VERSION ""

NS_ :

BS_:
BU_: Xsens_Sensor
BO_ 2147483648 VECTOR__INDEPENDENT_SIG_MSG: 0 Vector__XXX
   SG_ NewSignal_0016 : 0|8@1+ (1,0) [0|0] "" Vector__XXX

BO_ 1 Error: 1 Xsens_Sensor

BO_ 2 Warning: 1 Xsens_Sensor
   SG_ WarningCode : 7|8@0+ (1,0) [0|0] "" Vector__XXX

BO_ 5 SampleTime: 4 Xsens_Sensor
   SG_ Timestamp : 7|32@0+ (1,0) [0|0] "us" Vector__XXX

BO_ 6 GroupCounter: 2 Xsens_Sensor
   SG_ Counter : 7|16@0+ (1,0) [0|0] "" Vector__XXX

BO_ 17 StatusWord: 4 Xsens_Sensor
   SG_ SelfTestOk : 24|1@1+ (1,0) [0|1] "" Vector__XXX
   SG_ FilterValid : 25|1@1+ (1,0) [0|1] "" Vector__XXX
   SG_ GnssFix : 26|1@1+ (1,0) [0|1] "" Vector__XXX
   SG_ NoRotationStatus : 28|2@0+ (1,0) [0|3] "" Vector__XXX
   SG_ RepresentativeMotion : 29|1@1+ (1,0) [0|1] "" Vector__XXX
   SG_ ExternalClockSynced : 30|1@1+ (1,0) [0|1] "" Vector__XXX
   SG_ ClipAccX : 16|1@1+ (1,0) [0|1] "" Vector__XXX
   SG_ ClipAccY : 17|1@1+ (1,0) [0|1] "" Vector__XXX
   SG_ ClipAccZ : 18|1@1+ (1,0) [0|1] "" Vector__XXX
   SG_ ClipGyrX : 19|1@1+ (1,0) [0|1] "" Vector__XXX
   SG_ ClipGyrY : 20|1@1+ (1,0) [0|1] "" Vector__XXX
   SG_ ClipGyrZ : 21|1@1+ (1,0) [0|1] "" Vector__XXX
   SG_ ClipMagX : 22|1@1+ (1,0) [0|1] "" Vector__XXX
   SG_ ClipMagY : 23|1@1+ (1,0) [0|1] "" Vector__XXX
   SG_ ClipMagZ : 8|1@1+ (1,0) [0|1] "" Vector__XXX
   SG_ ClippingDetected : 11|1@1+ (1,0) [0|1] "" Vector__XXX
   SG_ SyncIn : 13|1@1+ (1,0) [0|1] "" Vector__XXX
   SG_ SyncOut : 14|1@1+ (1,0) [0|1] "" Vector__XXX
   SG_ FilterMode : 1|3@0+ (1,0) [0|1] "" Vector__XXX
   SG_ HaveGnssTimePulse : 2|1@1+ (1,0) [0|1] "" Vector__XXX
   SG_ RtkStatus : 4|2@0+ (1,0) [0|1] "" Vector__XXX

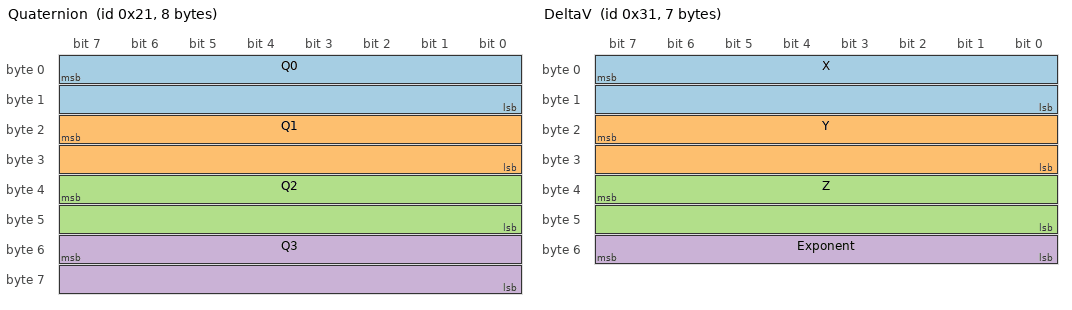
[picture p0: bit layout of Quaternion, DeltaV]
BO_ 33 Quaternion: 8 Xsens_Sensor
   SG_ Q0 : 7|16@0- (3.05176e-05,0) [-1|1] "" Vector__XXX
   SG_ Q1 : 23|16@0- (3.05176e-05,0) [-1|1] "" Vector__XXX
   SG_ Q2 : 39|16@0- (3.05176e-05,0) [-1|1] "" Vector__XXX
   SG_ Q3 : 55|16@0- (3.05176e-05,0) [-1|1] "" Vector__XXX

BO_ 49 DeltaV: 7 Xsens_Sensor
   SG_ X : 7|16@0- (7.62939e-06,0) [-0.25|0.25] "m/s" Vector__XXX
   SG_ Y : 23|16@0- (7.62939e-06,0) [-0.25|0.25] "m/s" Vector__XXX
   SG_ Z : 39|16@0- (7.62939e-06,0) [-0.25|0.25] "m/s" Vector__XXX
   SG_ Exponent : 55|8@0+ (1,0) [0|0] "" Vector__XXX

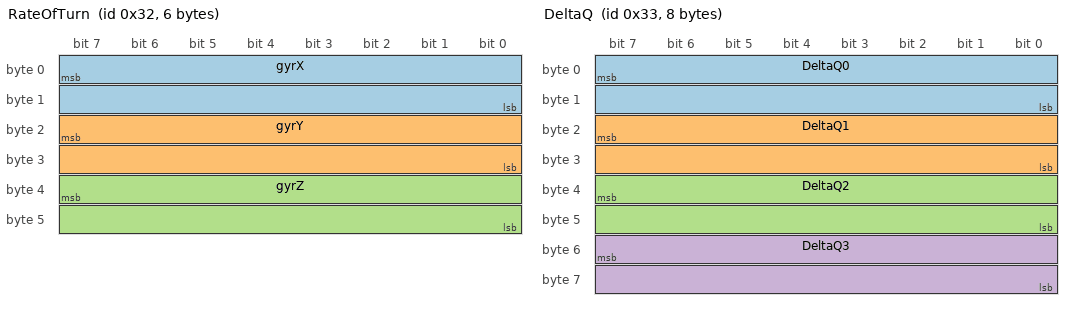
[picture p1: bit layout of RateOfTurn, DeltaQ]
BO_ 50 RateOfTurn: 6 Xsens_Sensor
   SG_ gyrX : 7|16@0- (0.00195313,0) [-35|35] "rad/s" Vector__XXX
   SG_ gyrY : 23|16@0- (0.00195313,0) [-35|35] "rad/s" Vector__XXX
   SG_ gyrZ : 39|16@0- (0.00195313,0) [-35|35] "rad/s" Vector__XXX

BO_ 51 DeltaQ: 8 Xsens_Sensor
   SG_ DeltaQ0 : 7|16@0- (3.05185e-05,0) [-1|1] "" Vector__XXX
   SG_ DeltaQ1 : 23|16@0- (3.05185e-05,0) [-1|1] "" Vector__XXX
   SG_ DeltaQ2 : 39|16@0- (3.05185e-05,0) [-1|1] "" Vector__XXX
   SG_ DeltaQ3 : 55|16@0- (3.05185e-05,0) [-1|1] "" Vector__XXX

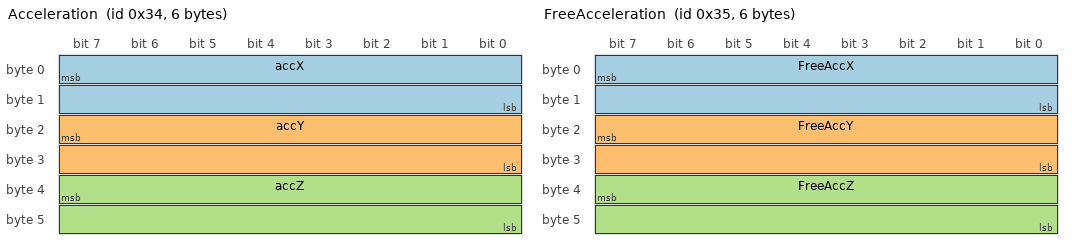
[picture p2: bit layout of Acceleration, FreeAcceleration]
BO_ 52 Acceleration: 6 Xsens_Sensor
   SG_ accX : 7|16@0- (0.00390625,0) [-100|100] "m/s²" Vector__XXX
   SG_ accY : 23|16@0- (0.00390625,0) [-100|100] "m/s²" Vector__XXX
   SG_ accZ : 39|16@0- (0.00390625,0) [-100|100] "m/s²" Vector__XXX

BO_ 53 FreeAcceleration: 6 Xsens_Sensor
   SG_ FreeAccX : 7|16@0- (0.00390625,0) [-100|100] "m/s²" Vector__XXX
   SG_ FreeAccY : 23|16@0- (0.00390625,0) [-100|100] "m/s²" Vector__XXX
   SG_ FreeAccZ : 39|16@0- (0.00390625,0) [-100|100] "m/s²" Vector__XXX

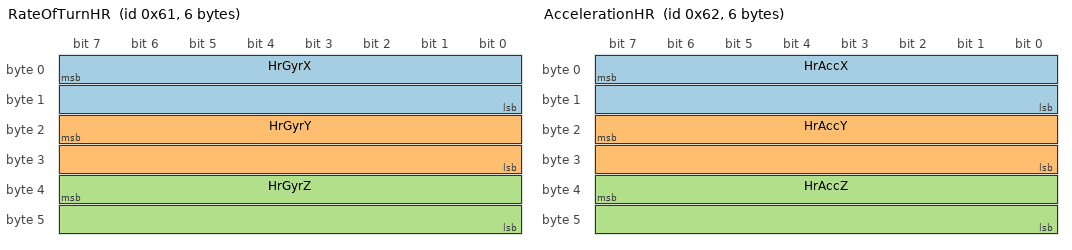
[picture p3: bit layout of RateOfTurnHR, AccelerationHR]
BO_ 97 RateOfTurnHR: 6 Xsens_Sensor
   SG_ HrGyrX : 7|16@0- (0.00195313,0) [-35|35] "rad/s" Vector__XXX
   SG_ HrGyrY : 23|16@0- (0.00195313,0) [-35|35] "rad/s" Vector__XXX
   SG_ HrGyrZ : 39|16@0- (0.00195313,0) [-35|35] "rad/s" Vector__XXX

BO_ 98 AccelerationHR: 6 Xsens_Sensor
   SG_ HrAccX : 7|16@0- (0.00390625,0) [-100|100] "m/s²" Vector__XXX
   SG_ HrAccY : 23|16@0- (0.00390625,0) [-100|100] "m/s²" Vector__XXX
   SG_ HrAccZ : 39|16@0- (0.00390625,0) [-100|100] "m/s²" Vector__XXX

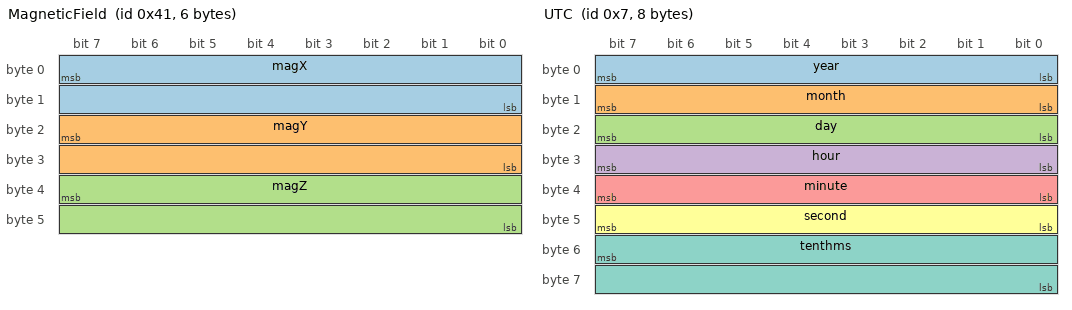
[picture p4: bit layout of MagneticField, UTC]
BO_ 65 MagneticField: 6 Xsens_Sensor
   SG_ magX : 7|16@0- (0.000976563,0) [-32|32] "a.u." Vector__XXX
   SG_ magY : 23|16@0- (0.000976563,0) [-32|32] "a.u" Vector__XXX
   SG_ magZ : 39|16@0- (0.000976563,0) [-32|32] "a.u" Vector__XXX

BO_ 81 Temperature: 2 Xsens_Sensor
   SG_ Temperature : 7|16@0- (0.00390625,0) [-40|85] "degC" Vector__XXX

BO_ 82 BarometricPressure: 4 Xsens_Sensor
   SG_ Pressure : 7|32@0+ (1,0) [30000|125000] "Pa" Vector__XXX

BO_ 7 UTC: 8 Xsens_Sensor
   SG_ year : 7|8@0+ (1,0) [0|0] "Y" Vector__XXX
   SG_ month : 15|8@0+ (1,0) [1|12] "M" Vector__XXX
   SG_ day : 23|8@0+ (1,0) [1|31] "D" Vector__XXX
   SG_ hour : 31|8@0+ (1,0) [0|24] "h" Vector__XXX
   SG_ minute : 39|8@0+ (1,0) [0|60] "m" Vector__XXX
   SG_ second : 47|8@0+ (1,0) [0|60] "s" Vector__XXX
   SG_ tenthms : 55|16@0+ (1,0) [0|0] "ms/10" Vector__XXX

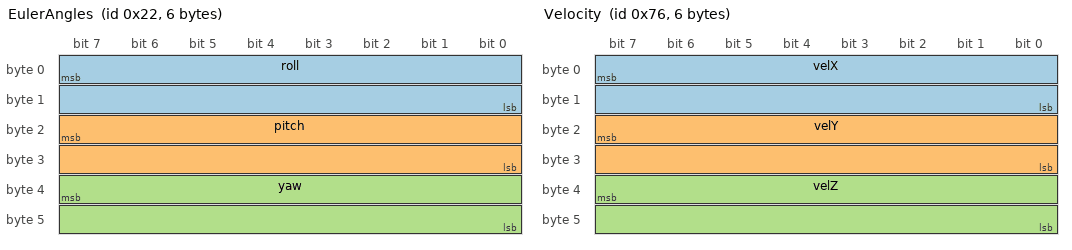
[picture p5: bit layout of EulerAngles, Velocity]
BO_ 34 EulerAngles: 6 Xsens_Sensor
   SG_ roll : 7|16@0- (0.0078125,0) [-180|180] "deg" Vector__XXX
   SG_ pitch : 23|16@0- (0.0078125,0) [-90|90] "deg" Vector__XXX
   SG_ yaw : 39|16@0- (0.0078125,0) [-180|180] "deg" Vector__XXX

BO_ 113 LatLon: 8 Xsens_Sensor
   SG_ latitude : 7|32@0- (5.96046e-08,0) [-90|90] "deg" Vector__XXX
   SG_ longitude : 39|32@0- (1.19209e-07,0) [-180|180] "deg" Vector__XXX

BO_ 114 AltitudeEllipsoid: 4 Xsens_Sensor
   SG_ altEllipsoid : 7|32@0- (3.05176e-05,0) [-1000|80000] "m" Vector__XXX

BO_ 115 PositionEcef_X: 4 Xsens_Sensor
   SG_ PositionEcef_X : 7|32@0- (0.00390625,0) [-6.5e+06|6.5e+06] "m" Vector__XXX

BO_ 116 PositionEcef_Y: 4 Xsens_Sensor
   SG_ PositionEcef_Y : 7|32@0- (0.00390625,0) [-6.5e+06|6.5e+06] "m" Vector__XXX

BO_ 117 PositionEcef_Z: 4 Xsens_Sensor
   SG_ PositionEcef_Z : 7|32@0- (0.00390625,0) [-6.5e+06|6.5e+06] "m" Vector__XXX

BO_ 118 Velocity: 6 Xsens_Sensor
   SG_ velX : 7|16@0- (0.015625,0) [-500|500] "m/s" Vector__XXX
   SG_ velY : 23|16@0- (0.015625,0) [-500|500] "m/s" Vector__XXX
   SG_ velZ : 39|16@0- (0.015625,0) [-500|500] "m/s" Vector__XXX

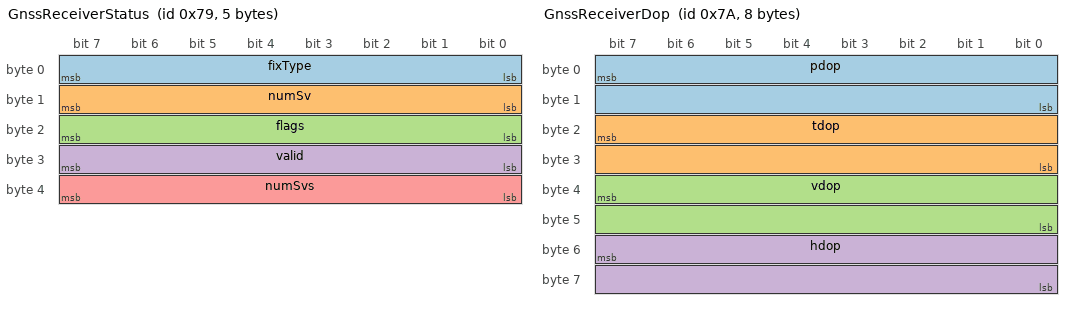
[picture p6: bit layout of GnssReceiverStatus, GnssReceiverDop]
BO_ 121 GnssReceiverStatus: 5 Xsens_Sensor
   SG_ fixType : 7|8@0+ (1,0) [0|5] "" Vector__XXX
   SG_ numSv : 15|8@0+ (1,0) [0|255] "" Vector__XXX
   SG_ flags : 23|8@0+ (1,0) [0|255] "" Vector__XXX
   SG_ valid : 31|8@0+ (1,0) [0|255] "" Vector__XXX
   SG_ numSvs : 39|8@0+ (1,0) [0|255] "" Vector__XXX

BO_ 122 GnssReceiverDop: 8 Xsens_Sensor
   SG_ pdop : 7|16@0+ (0.01,0) [0|100] "" Vector__XXX
   SG_ tdop : 23|16@0+ (0.01,0) [0|100] "" Vector__XXX
   SG_ vdop : 39|16@0+ (0.01,0) [0|100] "" Vector__XXX
   SG_ hdop : 55|16@0+ (0.01,0) [0|100] "" Vector__XXX

CM_ BU_ Xsens_Sensor "Generic Xsens Motion Sensor";
CM_ SG_ 17 SelfTestOk "Set when the self test result was ok";
CM_ SG_ 17 FilterValid "Set when the computed orientation is valid. The orientation may be invalid during startup or when the Xsens_Sensor data is clipping during violent (for the device) motion";
CM_ SG_ 17 GnssFix "Set when the device has a GNSS receiver and the receiver says that there is a GNSS position fix.";
CM_ SG_ 17 RepresentativeMotion "Indicates if the In-Run Compass Calibration is doing the representative motion analysis";
CM_ SG_ 17 ExternalClockSynced "Indicates whether the internal clock is synced with an external clock (Either GNSS or custom provided clock sync)";
CM_ SG_ 17 ClipAccX "Indicates if there was clipping on the X-axis of the accelerometer";
CM_ SG_ 17 ClipAccY "Indicates if there was clipping on the Y-axis of the accelerometer";
CM_ SG_ 17 ClipAccZ "Indicates if there was clipping on the Z-axis of the accelerometer";
CM_ SG_ 17 ClipGyrX "Indicates if there was clipping on the X-axis of the gyroscope";
CM_ SG_ 17 ClipGyrY "Indicates if there was clipping on the Y-axis of the gyroscope";
CM_ SG_ 17 ClipGyrZ "Indicates if there was clipping on the Z-axis of the gyroscope";
CM_ SG_ 17 ClipMagX "Indicates if there was clipping on the X-axis of the magnetometer";
CM_ SG_ 17 ClipMagY "Indicates if there was clipping on the Y-axis of the magnetometer";
CM_ SG_ 17 ClipMagZ "Indicates if there was clipping on the Z-axis of the magnetometer";
CM_ SG_ 17 ClippingDetected "When set Indicates clipping has occurred";
CM_ SG_ 17 SyncIn "When set indicates a sync-in event has been triggered";
CM_ SG_ 17 SyncOut "When set Indicates a sync-out event has been generated";
CM_ SG_ 17 FilterMode "Mask for the 3 bit filter mode field";
CM_ SG_ 17 HaveGnssTimePulse "Indicates that the 1PPS GNSS time pulse is present";
CM_ SG_ 17 RtkStatus "Mask for 2 bit RTK status field";
CM_ BO_ 7 "UTC Time in the following format YYMMDDhhmmss plus tenth of a milli second";
BA_DEF_ BO_ "GenMsgBackgroundColor" STRING ;
BA_DEF_ BO_ "GenMsgForegroundColor" STRING ;
BA_DEF_ BO_ "filterlabeling" INT 0 0;
BA_DEF_DEF_ "GenMsgBackgroundColor" "#ffffff";
BA_DEF_DEF_ "GenMsgForegroundColor" "#000000";
BA_DEF_DEF_ "filterlabeling" 1;
BA_ "GenMsgBackgroundColor" BO_ 34 "#ffff00";
BA_ "GenMsgBackgroundColor" BO_ 118 "#ff5500";
VAL_ 17 SelfTestOk 0 "false" 1 "true";
VAL_ 17 FilterValid 0 "false" 1 "true";
VAL_ 17 GnssFix 0 "false" 1 "true";
VAL_ 17 NoRotationStatus 1 "Aborted" 2 "SamplesRejected" 3 "RunningNormally";
VAL_ 17 RepresentativeMotion 0 "false" 1 "true";
VAL_ 17 ExternalClockSynced 0 "false" 1 "true";
VAL_ 17 ClipAccX 0 "false" 1 "true";
VAL_ 17 ClipAccY 0 "false" 1 "true";
VAL_ 17 ClipAccZ 0 "false" 1 "true";
VAL_ 17 ClipGyrX 0 "false" 1 "true";
VAL_ 17 ClipGyrY 0 "false" 1 "true";
VAL_ 17 ClipGyrZ 0 "false" 1 "true";
VAL_ 17 ClipMagX 0 "false" 1 "true";
VAL_ 17 ClipMagY 0 "false" 1 "true";
VAL_ 17 ClipMagZ 0 "false" 1 "true";
VAL_ 17 ClippingDetected 0 "false" 1 "true";
VAL_ 17 SyncIn 0 "false" 1 "true";
VAL_ 17 SyncOut 0 "false" 1 "true";
VAL_ 17 FilterMode 0 "false" 1 "true";
VAL_ 17 HaveGnssTimePulse 0 "false" 1 "true";
VAL_ 17 RtkStatus 0 "No RTK" 1 "RTK floating" 2 "RTK fixed";
